# STM32C091 register map
File version: 1.1
CPU: CM0+ r0p0, little endian, MPU, no FPU, 4 interrupt priority bits
Registers are 32-bit, read-write, reset 0x0 unless marked. A register's access mark holds for its fields unless they carry their own. Offsets are from the block's base; [hi:lo] are bit positions; {n}, {i} and the like mark numbered series; 'fields as' and 'values as' point back to an identical list.

## TIM15 — TIM15 address block description
Base 0x40014000
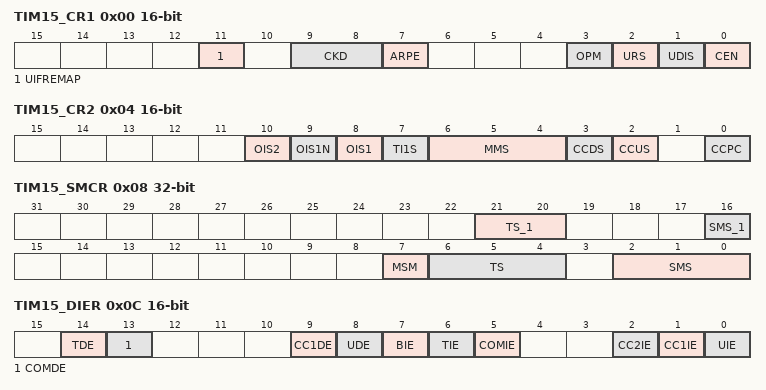
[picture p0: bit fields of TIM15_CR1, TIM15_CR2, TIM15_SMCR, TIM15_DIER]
0x00 TIM15_CR1 16-bit — TIM15 control register 1
  [11] UIFREMAP — UIF status bit remapping
    0=No remapping; 1=Remapping enabled
  [9:8] CKD — Clock division
    0=tless thansub>DTS less than/sub>= tless thansub>CK_INTless than/sub>; 1=tless thansub>DTSless than/sub> = 2*tless thansub>CK_INTless than/sub>; 2=tless thansub>DTSless than/sub> = 4*tless thansub>CK_INTless than/sub>
  [7] ARPE — Auto-reload preload enable
    0=TIMx_ARR register is not buffered; 1=TIMx_ARR register is buffered
  [3] OPM — One-pulse mode
    0=Counter is not stopped at update event; 1=Counter stops counting at the next update event (clearing the bit CEN)
  [2] URS — Update request source
    0=Any of the following events generate an update interrupt if enabled; 1=Only counter overflow/underflow generates an update interrupt if enabled
  [1] UDIS — Update disable
    0=UEV enabled; 1=UEV disabled
  [0] CEN — Counter enable
    0=Counter disabled; 1=Counter enabled
0x04 TIM15_CR2 16-bit — TIM15 control register 2
  [10] OIS2 — Output idle state 2 (OC2 output)
    0=OC2=0 when MOE=0; 1=OC2=1 when MOE=0
  [9] OIS1N — Output Idle state 1 (OC1N output)
    0=OC1N=0 after a dead-time when MOE=0; 1=OC1N=1 after a dead-time when MOE=0
  [8] OIS1 — Output Idle state 1 (OC1 output)
    0=OC1=0 (after a dead-time if OC1N is implemented) when MOE=0; 1=OC1=1 (after a dead-time if OC1N is implemented) when MOE=0
  [7] TI1S — TI1 selection
    0=The TIMx_CH1 pin is connected to TI1 input; 1=The TIMx_CH1, CH2 pins are connected to the TI1 input (XOR combination)
  [6:4] MMS — Master mode selection
    0=Reset - the UG bit from the TIMx_EGR register is used as trigger output (TRGO); 1=Enable - the Counter Enable signal CNT_EN is used as trigger output (TRGO); 2=Update - The update event is selected as trigger output (TRGO); 3=Compare Pulse - The trigger output send a positive pulse when the CC1IF flag is to be set (even if it was already high), as soon as a capture or a compare match occurred; 4=Compare - OC1REFC signal is used as trigger output (TRGO); 5=Compare - OC2REFC signal is used as trigger output (TRGO)
  [3] CCDS — Capture/compare DMA selection
    0=CCx DMA request sent when CCx event occurs; 1=CCx DMA requests sent when update event occurs
  [2] CCUS — Capture/compare control update selection
    0=When capture/compare control bits are preloaded (CCPC=1), they are updated by setting the COMG bit only; 1=When capture/compare control bits are preloaded (CCPC=1), they are updated by setting the COMG bit or when an rising edge occurs on TRGI
  [0] CCPC — Capture/compare preloaded control
    0=CCxE, CCxNE and OCxM bits are not preloaded; 1=CCxE, CCxNE and OCxM bits are preloaded, after having been written, they are updated only when a commutation event (COM) occurs (COMG bit set or rising edge detected on TRGI, depending on the CCUS bit)
0x08 TIM15_SMCR — TIM15 slave mode control register
  [21:20] TS_1 — TS[4:3]
  [16] SMS_1 — SMS[3]
  [7] MSM — Master/slave mode
    0=No action; 1=The effect of an event on the trigger input (TRGI) is delayed to allow a perfect synchronization between the current timer and its slaves (through TRGO)
  [6:4] TS — TS[2:0]: Trigger selection
    {v}=Internal Trigger {v} (ITR{v}) (v=0..3); 4=TI1 Edge Detector (TI1F_ED); 5=Filtered Timer Input 1 (TI1FP1); 6=Filtered Timer Input 2 (TI2FP2)
  [2:0] SMS — SMS[2:0]: Slave mode selection
    0=Slave mode disabled - if CEN = 1' then the prescaler is clocked directly by the internal clock; 4=Reset Mode - Rising edge of the selected trigger input (TRGI) reinitializes the counter and generates an update of the registers; 5=Gated Mode - The counter clock is enabled when the trigger input (TRGI) is high; 6=Trigger Mode - The counter starts at a rising edge of the trigger TRGI (but it is not reset); 7=External Clock Mode 1 - Rising edges of the selected trigger (TRGI) clock the counter
0x0C TIM15_DIER 16-bit — TIM15 DMA/interrupt enable register
  [14] TDE — Trigger DMA request enable
    0=Trigger DMA request disabled; 1=Trigger DMA request enabled
  [13] COMDE — COM DMA request enable
    0=COM DMA request disabled; 1=COM DMA request enabled
  [9] CC1DE — Capture/Compare 1 DMA request enable
    0=CC1 DMA request disabled; 1=CC1 DMA request enabled
  [8] UDE — Update DMA request enable
    0=Update DMA request disabled; 1=Update DMA request enabled
  [7] BIE — Break interrupt enable
    0=Break interrupt disabled; 1=Break interrupt enabled
  [6] TIE — Trigger interrupt enable
    0=Trigger interrupt disabled; 1=Trigger interrupt enabled
  [5] COMIE — COM interrupt enable
    0=COM interrupt disabled; 1=COM interrupt enabled
  [2] CC2IE — Capture/Compare 2 interrupt enable
    0=CC2 interrupt disabled; 1=CC2 interrupt enabled
  [1] CC1IE — Capture/Compare 1 interrupt enable
    0=CC1 interrupt disabled; 1=CC1 interrupt enabled
  [0] UIE — Update interrupt enable
    0=Update interrupt disabled; 1=Update interrupt enabled
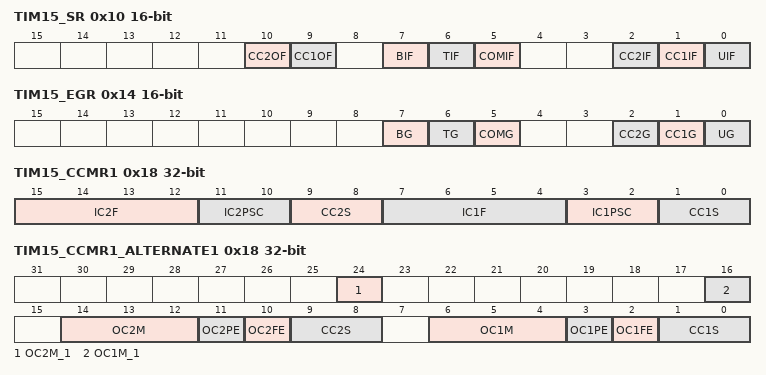
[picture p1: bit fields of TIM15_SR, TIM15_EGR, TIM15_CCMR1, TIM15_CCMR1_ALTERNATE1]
0x10 TIM15_SR 16-bit — TIM15 status register
  [10] CC2OF — Capture/Compare 2 overcapture flag
  [9] CC1OF — Capture/Compare 1 overcapture flag
    0=No overcapture has been detected; 1=The counter value has been captured in TIMx_CCR1 register while CC1IF flag was already set
  [7] BIF — Break interrupt flag
    0=No break event occurred; 1=An active level has been detected on the break input
  [6] TIF — Trigger interrupt flag
    0=No trigger event occurred; 1=Trigger interrupt pending
  [5] COMIF — COM interrupt flag
    0=No COM event occurred; 1=COM interrupt pending
  [2] CC2IF — Capture/Compare 2 interrupt flag
  [1] CC1IF — Capture/Compare 1 interrupt flag
    0=No compare match / No input capture occurred; 1=A compare match or an input capture occurred
  [0] UIF — Update interrupt flag
    0=No update occurred; 1=Update interrupt pending
0x14 TIM15_EGR 16-bit — TIM15 event generation register
  [7] BG wo — Break generation
    0=No action; 1=A break event is generated
  [6] TG wo — Trigger generation
    0=No action; 1=The TIF flag is set in TIMx_SR register
  [5] COMG — Capture/Compare control update generation
    0=No action; 1=When the CCPC bit is set, it is possible to update the CCxE, CCxNE and OCxM bits
  [2] CC2G wo — Capture/Compare 2 generation
  [1] CC1G wo — Capture/Compare 1 generation
    0=No action; 1=A capture/compare event is generated on channel 1:
  [0] UG wo — Update generation
    0=No action; 1=Reinitialize the counter and generates an update of the registers
0x18 TIM15_CCMR1 — TIM15 capture/compare mode register 1
  [15:12] IC2F — Input capture 2 filter
  [11:10] IC2PSC — Input capture 2 prescaler
  [9:8] CC2S — Capture/Compare 2 selection
    0=CC2 channel is configured as output; 1=CC2 channel is configured as input, IC2 is mapped on TI2; 2=CC2 channel is configured as input, IC2 is mapped on TI1; 3=CC2 channel is configured as input, IC2 is mapped on TRC
  [7:4] IC1F — Input capture 1 filter
    0=No filter, sampling is done at fless thansub>DTSless than/sub>; 1=fless thansub>SAMPLINGless than/sub>=fless thansub>CK_INTless than/sub>, N=2; 2=fless thansub>SAMPLINGless than/sub>=fless thansub>CK_INTless than/sub>, N=4; 3=fless thansub>SAMPLINGless than/sub>=fless thansub>CK_INTless than/sub>, N=8; 4=fless thansub>SAMPLINGless than/sub>=fless thansub>DTSless than/sub>/2, N=6; 5=fless thansub>SAMPLINGless than/sub>=fless thansub>DTSless than/sub>/2, N=8; 6=fless thansub>SAMPLINGless than/sub>=fless thansub>DTSless than/sub>/4, N=6; 7=fless thansub>SAMPLINGless than/sub>=fless thansub>DTSless than/sub>/4, N=8; 8=fless thansub>SAMPLINGless than/sub>=fless thansub>DTSless than/sub>/8, N=6; 9=fless thansub>SAMPLINGless than/sub>=fless thansub>DTSless than/sub>/8, N=8; 10=fless thansub>SAMPLINGless than/sub>=fless thansub>DTSless than/sub>/16, N=5; 11=fless thansub>SAMPLINGless than/sub>=fless thansub>DTSless than/sub>/16, N=6; 12=fless thansub>SAMPLINGless than/sub>=fless thansub>DTSless than/sub>/16, N=8; 13=fless thansub>SAMPLINGless than/sub>=fless thansub>DTSless than/sub>/32, N=5; 14=fless thansub>SAMPLINGless than/sub>=fless thansub>DTSless than/sub>/32, N=6; 15=fless thansub>SAMPLINGless than/sub>=fless thansub>DTSless than/sub>/32, N=8
  [3:2] IC1PSC — Input capture 1 prescaler
    0=no prescaler, capture is done each time an edge is detected on the capture input; 1=capture is done once every 2 events; 2=capture is done once every 4 events; 3=capture is done once every 8 events
  [1:0] CC1S — Capture/Compare 1 Selection
    0=CC1 channel is configured as output; 1=CC1 channel is configured as input, IC1 is mapped on TI1; 2=CC1 channel is configured as input, IC1 is mapped on TI2; 3=CC1 channel is configured as input, IC1 is mapped on TRC
0x18 TIM15_CCMR1_ALTERNATE1 (alternate view of TIM15_CCMR1) — TIM15 capture/compare mode register 1
  [24] OC2M_1 — OC2M[3]
  [16] OC1M_1 — OC1M[3]
  [14:12] OC2M — OC2M[2:0]: Output Compare 2 mode
  [11] OC2PE — Output Compare 2 preload enable
  [10] OC2FE — Output Compare 2 fast enable
  [9:8] CC2S — Capture/Compare 2 selection
    values as TIM15_CCMR1.CC2S
  [6:4] OC1M — OC1M[2:0]: Output Compare 1 mode
    0=Frozen - The comparison between the output compare register TIMx_CCR1 and the counter TIMx_CNT has no effect on the outputs; 1=Set channel 1 to active level on match; 2=Set channel 1 to inactive level on match; 3=Toggle - OC1REF toggles when TIMx_CNT=TIMx_CCR1; 4=Force inactive level - OC1REF is forced low; 5=Force active level - OC1REF is forced high; 6=PWM mode 1 - Channel 1 is active as long as TIMx_CNTless thanTIMx_CCR1 else inactive; 7=PWM mode 2 - Channel 1 is inactive as long as TIMx_CNTless thanTIMx_CCR1 else active
  [3] OC1PE — Output Compare 1 preload enable
    0=Preload register on TIMx_CCR1 disabled; 1=Preload register on TIMx_CCR1 enabled
  [2] OC1FE — Output Compare 1 fast enable
    0=CC1 behaves normally depending on counter and CCR1 values even when the trigger is ON; 1=An active edge on the trigger input acts like a compare match on CC1 output
  [1:0] CC1S — Capture/Compare 1 selection
    values as TIM15_CCMR1.CC1S
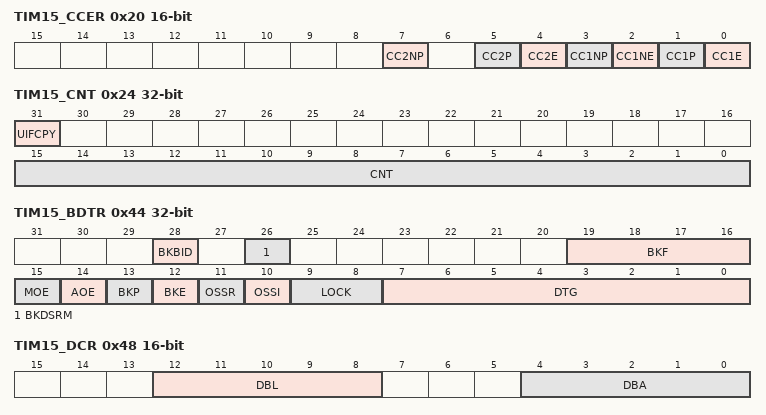
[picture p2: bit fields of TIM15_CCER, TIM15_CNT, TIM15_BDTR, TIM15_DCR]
0x20 TIM15_CCER 16-bit — TIM15 capture/compare enable register
  [7] CC2NP — Capture/Compare 2 complementary output polarity
  [5] CC2P — Capture/Compare 2 output polarity
  [4] CC2E — Capture/Compare 2 output enable
  [3] CC1NP — Capture/Compare 1 complementary output polarity
    0=OC1N active high; 1=OC1N active low
  [2] CC1NE — Capture/Compare 1 complementary output enable
    0=Off - OC1N is not active; 1=On - OC1N signal is output on the corresponding output pin depending on MOE, OSSI, OSSR, OIS1, OIS1N and CC1E bits
  [1] CC1P — Capture/Compare 1 output polarity
    0=OC1 active high (output mode) / Edge sensitivity selection (input mode, see below); 1=OC1 active low (output mode) / Edge sensitivity selection (input mode, see below)
  [0] CC1E — Capture/Compare 1 output enable
    0=Capture mode disabled / OC1 is not active (see below); 1=Capture mode enabled / OC1 signal is output on the corresponding output pin
0x24 TIM15_CNT — TIM15 counter
  [31] UIFCPY ro — UIF Copy
  [15:0] CNT — Counter value
0x28 TIM15_PSC 16-bit — TIM15 prescaler
  [15:0] PSC — Prescaler value
0x2C TIM15_ARR 16-bit reset 0xFFFF — TIM15 auto-reload register
  [15:0] ARR — Auto-reload value
0x30 TIM15_RCR 16-bit — TIM15 repetition counter register
  [7:0] REP — Repetition counter value
0x34 TIM15_CCR1 16-bit — TIM15 capture/compare register 1
  [15:0] CCR1 — Capture/Compare 1 value
0x38 TIM15_CCR2 16-bit — TIM15 capture/compare register 2
  [15:0] CCR2 — Capture/Compare 2 value
0x44 TIM15_BDTR — TIM15 break and dead-time register
  [28] BKBID — Break Bidirectional
    0=Break input BRK in input mode; 1=Break input BRK in bidirectional mode
  [26] BKDSRM — Break Disarm
    0=Break input BRK is armed; 1=Break input BRK is disarmed
  [19:16] BKF — Break filter
    0=No filter, BRK acts asynchronously; 1=fless thansub>SAMPLINGless than/sub>=fless thansub>CK_INTless than/sub>, N=2; 2=fless thansub>SAMPLINGless than/sub>=fless thansub>CK_INTless than/sub>, N=4; 3=fless thansub>SAMPLINGless than/sub>=fless thansub>CK_INTless than/sub>, N=8; 4=fless thansub>SAMPLINGless than/sub>=fless thansub>DTSless than/sub>/2, N=6; 5=fless thansub>SAMPLINGless than/sub>=fless thansub>DTSless than/sub>/2, N=8; 6=fless thansub>SAMPLINGless than/sub>=fless thansub>DTSless than/sub>/4, N=6; 7=fless thansub>SAMPLINGless than/sub>=fless thansub>DTSless than/sub>/4, N=8; 8=fless thansub>SAMPLINGless than/sub>=fless thansub>DTSless than/sub>/8, N=6; 9=fless thansub>SAMPLINGless than/sub>=fless thansub>DTSless than/sub>/8, N=8; 10=fless thansub>SAMPLINGless than/sub>=fless thansub>DTSless than/sub>/16, N=5; 11=fless thansub>SAMPLINGless than/sub>=fless thansub>DTSless than/sub>/16, N=6; 12=fless thansub>SAMPLINGless than/sub>=fless thansub>DTSless than/sub>/16, N=8; 13=fless thansub>SAMPLINGless than/sub>=fless thansub>DTSless than/sub>/32, N=5; 14=fless thansub>SAMPLINGless than/sub>=fless thansub>DTSless than/sub>/32, N=6; 15=fless thansub>SAMPLINGless than/sub>=fless thansub>DTSless than/sub>/32, N=8
  [15] MOE — Main output enable
    0=OC and OCN outputs are disabled or forced to idle state depending on the OSSI bit; 1=OC and OCN outputs are enabled if their respective enable bits are set (CCxE, CCxNE in TIMx_CCER register)
  [14] AOE — Automatic output enable
    0=MOE can be set only by software; 1=MOE can be set by software or automatically at the next update event (if the break input is not be active)
  [13] BKP — Break polarity
    0=Break input BRK is active low; 1=Break input BRK is active high
  [12] BKE — Break enable
    0=Break inputs (BRK and CCS clock failure event) disabled
  [11] OSSR — Off-state selection for Run mode
    0=When inactive, OC/OCN outputs are disabled (the timer releases the output control which is taken over by the GPIO, which forces a Hi-Z state); 1=When inactive, OC/OCN outputs are enabled with their inactive level as soon as CCxE=1 or CCxNE=1 (the output is still controlled by the timer)
  [10] OSSI — Off-state selection for Idle mode
    0=When inactive, OC/OCN outputs are disabled (OC/OCN enable output signal=0); 1=When inactive, OC/OCN outputs are forced first with their idle level as soon as CCxE=1 or CCxNE=1
  [9:8] LOCK — Lock configuration
    0=LOCK OFF - No bit is write protected; 1=LOCK Level 1 = DTG bits in TIMx_BDTR register, OISx and OISxN bits in TIMx_CR2 register and BKE/BKP/AOE bits in TIMx_BDTR register can no longer be written; 2=LOCK Level 2 = LOCK Level 1 + CC Polarity bits (CCxP/CCxNP bits in TIMx_CCER register, as long as the related channel is configured in output through the CCxS bits) as well as OSSR and OSSI bits can no longer be written; 3=LOCK Level 3 = LOCK Level 2 + CC Control bits (OCxM and OCxPE bits in TIMx_CCMRx registers, as long as the related channel is configured in output through the CCxS bits) can no longer be written
  [7:0] DTG — Dead-time generator setup
0x48 TIM15_DCR 16-bit — TIM15 DMA control register
  [12:8] DBL — DMA burst length
    0=1 transfer,; 1=2 transfers,; 2=3 transfers,; 17=18 transfers
  [4:0] DBA — DMA base address
    0=TIMx_CR1,; 1=TIMx_CR2,; 2=TIMx_SMCR,
0x4C TIM15_DMAR 16-bit — TIM15 DMA address for full transfer
  [15:0] DMAB — DMA register for burst accesses
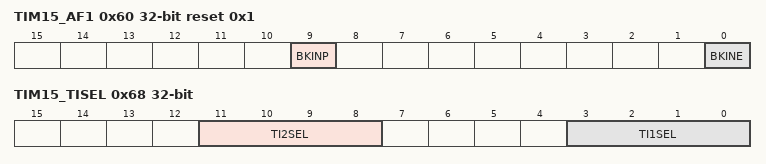
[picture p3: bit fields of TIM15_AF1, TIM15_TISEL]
0x60 TIM15_AF1 reset 0x1 — TIM15 alternate register 1
  [9] BKINP — BRK BKIN input polarity
    0=BKIN input is active low; 1=BKIN input is active high
  [0] BKINE — BRK BKIN input enable
    0=BKIN input disabled; 1=BKIN input enabled
0x68 TIM15_TISEL — TIM15 input selection register
  [11:8] TI2SEL — selects TI2[0] to TI2[15] input
    0=TIM15_CH2 input; 1=TIM2_IC2; 2=TIM3_IC2
  [3:0] TI1SEL — selects TI1[0] to TI1[15] input
    0=TIM15_CH1 input; 1=TIM2_IC1; 2=TIM3_IC1
